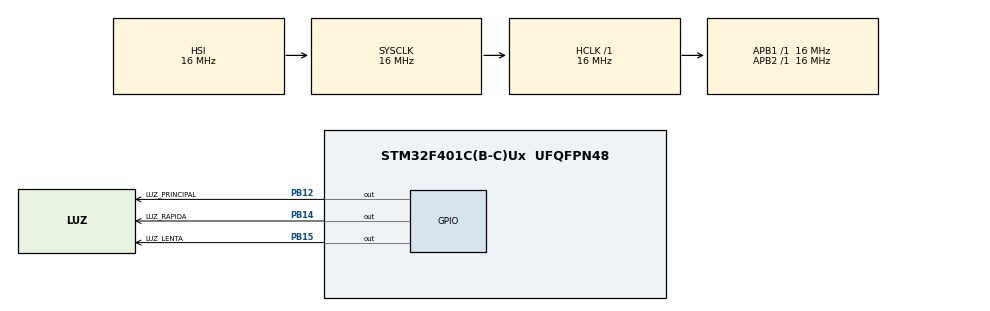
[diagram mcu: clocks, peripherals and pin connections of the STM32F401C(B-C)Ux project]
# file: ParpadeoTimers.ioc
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Mcu.Family=STM32F4
Mcu.Name=STM32F401C(B-C)Ux
Mcu.Package=UFQFPN48
NVIC.PriorityGroup=NVIC_PRIORITYGROUP_4
NVIC.TIM3_IRQn=true\:1\:0\:true\:false\:true\:true\:true\:true
NVIC.TIM4_IRQn=true\:2\:0\:true\:false\:true\:true\:true\:true
PB12.GPIO_Label=LUZ_PRINCIPAL
PB12.Signal=GPIO_Output
PB14.GPIO_Label=LUZ_RAPIDA
PB14.Signal=GPIO_Output
PB15.GPIO_Label=LUZ_LENTA
PB15.Signal=GPIO_Output
TIM3.AutoReloadPreload=TIM_AUTORELOAD_PRELOAD_ENABLE
TIM3.Period=2500-1
TIM3.Prescaler=1600-1
VP_TIM3_VS_ClockSourceINT.Mode=Internal
TIM4.AutoReloadPreload=TIM_AUTORELOAD_PRELOAD_ENABLE
TIM4.Period=1000-1
TIM4.Prescaler=16000-1
VP_TIM4_VS_ClockSourceINT.Mode=Internal
ProjectManager.HeapSize=0x200
ProjectManager.StackSize=0x400
ProjectManager.TargetToolchain=CMake
RCC.AHBFreq_Value=16000000
RCC.APB1Freq_Value=16000000
RCC.APB2Freq_Value=16000000
RCC.CortexFreq_Value=16000000
RCC.HSE_VALUE=25000000
RCC.HSI_VALUE=16000000
RCC.LSE_VALUE=32768
RCC.SYSCLKFreq_VALUE=16000000
RCC.VCOOutputFreq_Value=192000000
board=custom

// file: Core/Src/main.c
/* USER CODE BEGIN Header */
/**
  ******************************************************************************
  * @file           : main.c
  * @brief          : ParpadeoTimers
  *
  * Tres luces que parpadean a ritmos distintos usando tres mecanismos:
  *   - LUZ_PRINCIPAL (PB12): en el lazo principal, sin bloquear, con HAL_GetTick()
  *   - LUZ_RAPIDA    (PB14): interrupción de TIM3 cada 250 ms
  *   - LUZ_LENTA     (PB15): interrupción de TIM4 cada 1000 ms
  *
  * Reloj: HSI 16 MHz (sin PLL).
  ******************************************************************************
  */
/* USER CODE END Header */
#include "main.h"

/* USER CODE BEGIN Includes */
#include <stdint.h>
/* USER CODE END Includes */

/* USER CODE BEGIN PD */
#define PERIODO_PRINCIPAL_MS   500U   /* medio periodo de la luz del lazo principal */
/* USER CODE END PD */

TIM_HandleTypeDef htim3;
TIM_HandleTypeDef htim4;

/* USER CODE BEGIN PV */
static uint32_t marcaTiempoPrincipal = 0;    /* último instante en que cambió LUZ_PRINCIPAL */
volatile uint32_t conteoRapida = 0;          /* veces que ha disparado TIM3 */
volatile uint32_t conteoLenta  = 0;          /* veces que ha disparado TIM4 */
/* USER CODE END PV */

void SystemClock_Config(void);
static void MX_GPIO_Init(void);
static void MX_TIM3_Init(void);
static void MX_TIM4_Init(void);
/* USER CODE BEGIN PFP */
static void ActualizarLuzPrincipal(void);
/* USER CODE END PFP */

/* USER CODE BEGIN 0 */

/**
  * @brief  Cambia LUZ_PRINCIPAL cada PERIODO_PRINCIPAL_MS sin usar HAL_Delay,
  *         así el lazo principal queda libre para otras tareas.
  */
static void ActualizarLuzPrincipal(void)
{
  uint32_t ahora = HAL_GetTick();

  if ((ahora - marcaTiempoPrincipal) >= PERIODO_PRINCIPAL_MS)
  {
    marcaTiempoPrincipal = ahora;
    HAL_GPIO_TogglePin(LUZ_PRINCIPAL_GPIO_Port, LUZ_PRINCIPAL_Pin);
  }
}

/**
  * @brief  Callback común de los timers. La HAL lo llama desde
  *         HAL_TIM_IRQHandler() cuando un timer llega a su periodo.
  */
void HAL_TIM_PeriodElapsedCallback(TIM_HandleTypeDef *htim)
{
  if (htim->Instance == TIM3)
  {
    conteoRapida++;
    HAL_GPIO_TogglePin(LUZ_RAPIDA_GPIO_Port, LUZ_RAPIDA_Pin);
  }
  else if (htim->Instance == TIM4)
  {
    conteoLenta++;
    HAL_GPIO_TogglePin(LUZ_LENTA_GPIO_Port, LUZ_LENTA_Pin);
  }
}

/* USER CODE END 0 */

int main(void)
{

  /* MCU Configuration--------------------------------------------------------*/

  /* Reset of all peripherals, Initializes the Flash interface and the Systick. */
  HAL_Init();

  /* Configure the system clock */
  SystemClock_Config();

  /* Initialize all configured peripherals */
  MX_GPIO_Init();
  MX_TIM3_Init();
  MX_TIM4_Init();
  /* USER CODE BEGIN 2 */
  /* Arranca los dos timers en modo interrupción */
  if (HAL_TIM_Base_Start_IT(&htim3) != HAL_OK)
  {
    Error_Handler();
  }
  if (HAL_TIM_Base_Start_IT(&htim4) != HAL_OK)
  {
    Error_Handler();
  }
  marcaTiempoPrincipal = HAL_GetTick();
  /* USER CODE END 2 */

  /* Infinite loop */
  /* USER CODE BEGIN WHILE */
  while (1)
  {
    ActualizarLuzPrincipal();
    /* USER CODE END WHILE */

  }
}

void SystemClock_Config(void)
{
  RCC_OscInitTypeDef RCC_OscInitStruct = {0};
  RCC_ClkInitTypeDef RCC_ClkInitStruct = {0};

  /** Configure the main internal regulator output voltage
  */
  __HAL_RCC_PWR_CLK_ENABLE();
  __HAL_PWR_VOLTAGESCALING_CONFIG(PWR_REGULATOR_VOLTAGE_SCALE2);

  /** Initializes the RCC Oscillators according to the specified parameters
  * in the RCC_OscInitTypeDef structure.
  */
  RCC_OscInitStruct.OscillatorType = RCC_OSCILLATORTYPE_HSI;
  RCC_OscInitStruct.HSIState = RCC_HSI_ON;
  RCC_OscInitStruct.HSICalibrationValue = RCC_HSICALIBRATION_DEFAULT;
  RCC_OscInitStruct.PLL.PLLState = RCC_PLL_NONE;
  if (HAL_RCC_OscConfig(&RCC_OscInitStruct) != HAL_OK)
  {
    Error_Handler();
  }

  /** Initializes the CPU, AHB and APB buses clocks
  */
  RCC_ClkInitStruct.ClockType = RCC_CLOCKTYPE_HCLK|RCC_CLOCKTYPE_SYSCLK
                              |RCC_CLOCKTYPE_PCLK1|RCC_CLOCKTYPE_PCLK2;
  RCC_ClkInitStruct.SYSCLKSource = RCC_SYSCLKSOURCE_HSI;
  RCC_ClkInitStruct.AHBCLKDivider = RCC_SYSCLK_DIV1;
  RCC_ClkInitStruct.APB1CLKDivider = RCC_HCLK_DIV1;
  RCC_ClkInitStruct.APB2CLKDivider = RCC_HCLK_DIV1;

  if (HAL_RCC_ClockConfig(&RCC_ClkInitStruct, FLASH_LATENCY_0) != HAL_OK)
  {
    Error_Handler();
  }
}

static void MX_TIM3_Init(void)
{

  TIM_ClockConfigTypeDef sClockSourceConfig = {0};
  TIM_MasterConfigTypeDef sMasterConfig = {0};

  htim3.Instance = TIM3;
  htim3.Init.Prescaler = 1600-1;
  htim3.Init.CounterMode = TIM_COUNTERMODE_UP;
  htim3.Init.Period = 2500-1;
  htim3.Init.ClockDivision = TIM_CLOCKDIVISION_DIV1;
  htim3.Init.AutoReloadPreload = TIM_AUTORELOAD_PRELOAD_ENABLE;
  if (HAL_TIM_Base_Init(&htim3) != HAL_OK)
  {
    Error_Handler();
  }
  sClockSourceConfig.ClockSource = TIM_CLOCKSOURCE_INTERNAL;
  if (HAL_TIM_ConfigClockSource(&htim3, &sClockSourceConfig) != HAL_OK)
  {
    Error_Handler();
  }
  sMasterConfig.MasterOutputTrigger = TIM_TRGO_RESET;
  sMasterConfig.MasterSlaveMode = TIM_MASTERSLAVEMODE_DISABLE;
  if (HAL_TIMEx_MasterConfigSynchronization(&htim3, &sMasterConfig) != HAL_OK)
  {
    Error_Handler();
  }

}

static void MX_TIM4_Init(void)
{

  TIM_ClockConfigTypeDef sClockSourceConfig = {0};
  TIM_MasterConfigTypeDef sMasterConfig = {0};

  htim4.Instance = TIM4;
  htim4.Init.Prescaler = 16000-1;
  htim4.Init.CounterMode = TIM_COUNTERMODE_UP;
  htim4.Init.Period = 1000-1;
  htim4.Init.ClockDivision = TIM_CLOCKDIVISION_DIV1;
  htim4.Init.AutoReloadPreload = TIM_AUTORELOAD_PRELOAD_ENABLE;
  if (HAL_TIM_Base_Init(&htim4) != HAL_OK)
  {
    Error_Handler();
  }
  sClockSourceConfig.ClockSource = TIM_CLOCKSOURCE_INTERNAL;
  if (HAL_TIM_ConfigClockSource(&htim4, &sClockSourceConfig) != HAL_OK)
  {
    Error_Handler();
  }
  sMasterConfig.MasterOutputTrigger = TIM_TRGO_RESET;
  sMasterConfig.MasterSlaveMode = TIM_MASTERSLAVEMODE_DISABLE;
  if (HAL_TIMEx_MasterConfigSynchronization(&htim4, &sMasterConfig) != HAL_OK)
  {
    Error_Handler();
  }

}

static void MX_GPIO_Init(void)
{
  GPIO_InitTypeDef GPIO_InitStruct = {0};

  /* GPIO Ports Clock Enable */
  __HAL_RCC_GPIOB_CLK_ENABLE();

  /*Configure GPIO pin Output Level */
  HAL_GPIO_WritePin(GPIOB, LUZ_PRINCIPAL_Pin|LUZ_RAPIDA_Pin|LUZ_LENTA_Pin, GPIO_PIN_RESET);

  /*Configure GPIO pins : LUZ_PRINCIPAL_Pin LUZ_RAPIDA_Pin LUZ_LENTA_Pin */
  GPIO_InitStruct.Pin = LUZ_PRINCIPAL_Pin|LUZ_RAPIDA_Pin|LUZ_LENTA_Pin;
  GPIO_InitStruct.Mode = GPIO_MODE_OUTPUT_PP;
  GPIO_InitStruct.Pull = GPIO_NOPULL;
  GPIO_InitStruct.Speed = GPIO_SPEED_FREQ_LOW;
  HAL_GPIO_Init(GPIOB, &GPIO_InitStruct);

}

void Error_Handler(void)
{
  __disable_irq();
  while (1)
  {
  }
}
#ifdef USE_FULL_ASSERT
/**
  * @brief  Reports the name of the source file and the source line number
  *         where the assert_param error has occurred.
  * @param  file: pointer to the source file name
  * @param  line: assert_param error line source number
  * @retval None
  */
void assert_failed(uint8_t *file, uint32_t line)
{
  /* USER CODE BEGIN 6 */
  (void)file;
  (void)line;
  /* USER CODE END 6 */
}
#endif /* USE_FULL_ASSERT */
